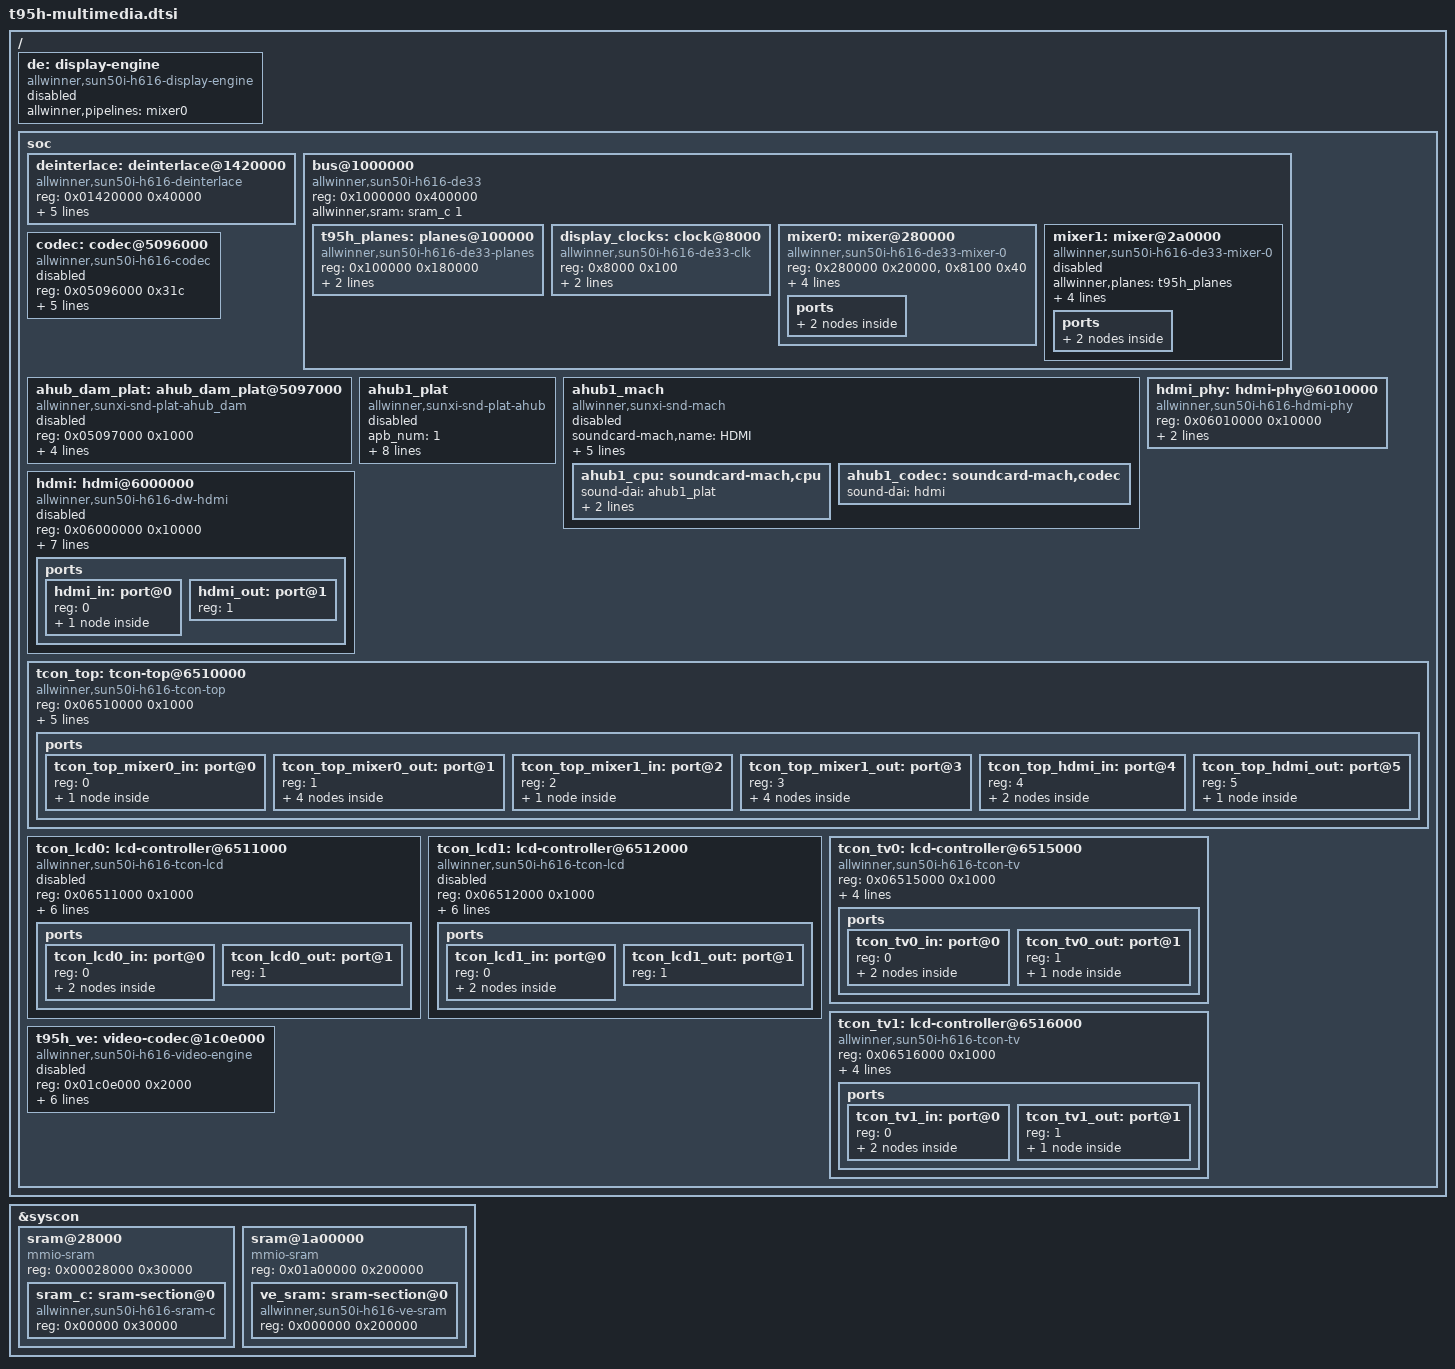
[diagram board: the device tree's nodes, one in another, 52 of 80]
// SPDX-License-Identifier: (GPL-2.0+ OR MIT)
// Staged 6.12 backport of tested T95H multimedia topology.
#include <dt-bindings/clock/sun8i-de2.h>
#include <dt-bindings/clock/sun8i-tcon-top.h>
#include <dt-bindings/reset/sun8i-de2.h>
/ {
	de: display-engine {
		compatible = "allwinner,sun50i-h616-display-engine", "allwinner,sun50i-h6-display-engine";
		allwinner,pipelines = <&mixer0>;
		status = "disabled";
	};
soc {
        deinterlace: deinterlace@1420000 {
            compatible = "allwinner,sun50i-h616-deinterlace";
            reg = <0x01420000 0x40000>;
            clocks = <&ccu CLK_BUS_DEINTERLACE>, <&ccu CLK_DEINTERLACE>;
            clock-names = "bus", "mod";
            resets = <&ccu RST_BUS_DEINTERLACE>;
            interrupts = <GIC_SPI 89 IRQ_TYPE_LEVEL_HIGH>;
            iommus = <&iommu 1>;
            status = "okay";
        };

		bus@1000000 {
			compatible = "allwinner,sun50i-h616-de33",
				     "allwinner,sun50i-a64-de2";
			reg = <0x1000000 0x400000>;
			allwinner,sram = <&sram_c 1>;
			#address-cells = <1>;
			#size-cells = <1>;
			ranges = <0 0x1000000 0x400000>;

			t95h_planes: planes@100000 {
                compatible = "allwinner,sun50i-h616-de33-planes";
                reg = <0x100000 0x180000>;
                allwinner,plane-mapping = <&display_clocks>;
                iommus = <&iommu 0>;
            };
            display_clocks: clock@8000 {
				compatible = "allwinner,sun50i-h616-de33-clk";
				reg = <0x8000 0x100>;
				clocks = <&ccu CLK_BUS_DE>, <&ccu CLK_DE>;
				clock-names = "bus", "mod";
				resets = <&ccu RST_BUS_DE>;
				#clock-cells = <1>;
				#reset-cells = <1>;
			};



			mixer0: mixer@280000 {
				compatible = "allwinner,sun50i-h616-de33-mixer-0";
				reg = <0x280000 0x20000>, <0x8100 0x40>;
				reg-names = "display", "top";
                allwinner,planes = <&t95h_planes>;
				clocks = <&display_clocks CLK_BUS_MIXER0>,
					 <&display_clocks CLK_MIXER0>;
				clock-names = "bus", "mod";
				resets = <&display_clocks RST_MIXER0>;

				ports {
					#address-cells = <1>;
					#size-cells = <0>;

					mixer0_out: port@1 {
						reg = <1>;

						mixer0_out_tcon_top_mixer0: endpoint {
							remote-endpoint =
								<&tcon_top_mixer0_in_mixer0>;
						};
					};
				};
			};

			mixer1: mixer@2a0000 {
                allwinner,planes = <&t95h_planes>;
				status = "disabled";
				compatible = "allwinner,sun50i-h616-de33-mixer-0";
				reg = <0x2a0000 0x20000>,
				      <0x8140 0x40>;
				reg-names = "display", "top";
				clocks = <&display_clocks CLK_BUS_MIXER0>,
					 <&display_clocks CLK_MIXER1>;
				clock-names = "bus", "mod";
				resets = <&display_clocks RST_MIXER1>;

				ports {
					#address-cells = <1>;
					#size-cells = <0>;

					mixer1_out: port@1 {
						reg = <1>;

						mixer1_out_tcon_top_mixer1: endpoint {
							remote-endpoint =
								<&tcon_top_mixer1_in_mixer1>;
						};
					};
				};
			};
		};
		codec: codec@5096000 {
			#sound-dai-cells = <0>;
			compatible = "allwinner,sun50i-h616-codec";
			reg = <0x05096000 0x31c>;
			interrupts = <GIC_SPI 58 IRQ_TYPE_LEVEL_HIGH>;
			clocks = <&ccu CLK_BUS_AUDIO_CODEC>,
				 <&ccu CLK_AUDIO_CODEC_1X>;
			clock-names = "apb", "codec";
			resets = <&ccu RST_BUS_AUDIO_CODEC>;
			dmas = <&dma 6>;
			dma-names = "tx";
			status = "disabled";
		};
		ahub_dam_plat:ahub_dam_plat@5097000 {
			#sound-dai-cells = <0>;
			/* sound card without pcm for hardware mix setting */
			compatible = "allwinner,sunxi-snd-plat-ahub_dam";
			reg        = <0x05097000 0x1000>;
			resets     = <&ccu RST_BUS_AUDIO_HUB>;
			clocks     = <&ccu CLK_AUDIO_CODEC_1X>,
				     <&ccu CLK_AUDIO_CODEC_4X>,
				     <&ccu CLK_AUDIO_HUB>,
				     <&ccu CLK_BUS_AUDIO_HUB>;
                        clock-names =   "clk_pll_audio",
					"clk_pll_audio_4x",
					"clk_audio_hub",
					"clk_bus_audio_hub";
			status = "disabled";
		};
		ahub1_plat:ahub1_plat {
			#sound-dai-cells = <0>;
			compatible      = "allwinner,sunxi-snd-plat-ahub";
			apb_num         = <1>;  /* for dma port 4 */
			dmas            = <&dma 4>, <&dma 4>;
			dma-names       = "tx", "rx";
			playback_cma    = <128>;
			capture_cma     = <128>;
			tx_fifo_size    = <128>;
			rx_fifo_size    = <128>;

			tdm_num         = <1>;
			tx_pin          = <0>;
			rx_pin          = <0>;
			status          = "disabled";
		};
		ahub1_mach:ahub1_mach {
			compatible = "allwinner,sunxi-snd-mach";
			soundcard-mach,name = "HDMI";

			soundcard-mach,format           = "i2s";
			soundcard-mach,frame-master     = <&ahub1_cpu>;
			soundcard-mach,bitclock-master  = <&ahub1_cpu>;
			/* soundcard-mach,frame-inversion; */
			/* soundcard-mach,bitclock-inversion; */
			soundcard-mach,slot-num         = <2>;
			soundcard-mach,slot-width       = <32>;
			status          = "disabled";
			ahub1_cpu: soundcard-mach,cpu {
				sound-dai = <&ahub1_plat>;
				soundcard-mach,pll-fs   = <4>;
				soundcard-mach,mclk-fs  = <0>;
			};

			ahub1_codec: soundcard-mach,codec {
				sound-dai = <&hdmi>;
			};
		};
		hdmi: hdmi@6000000 {
			compatible = "allwinner,sun50i-h616-dw-hdmi",
				     "allwinner,sun50i-h6-dw-hdmi";
			reg = <0x06000000 0x10000>;
			reg-io-width = <1>;
			interrupts = <GIC_SPI 63 IRQ_TYPE_LEVEL_HIGH>;
			clocks = <&ccu CLK_BUS_HDMI>, <&ccu CLK_HDMI_SLOW>,
				 <&ccu CLK_HDMI>, <&ccu CLK_HDMI_CEC>,
				 <&ccu CLK_HDCP>, <&ccu CLK_BUS_HDCP>;
			clock-names = "iahb", "isfr", "tmds", "cec", "hdcp",
				      "hdcp-bus";
			resets = <&ccu RST_BUS_HDMI>, <&ccu RST_BUS_HDCP>;
			reset-names = "ctrl", "hdcp";
			phys = <&hdmi_phy>;
			phy-names = "phy";
			status = "disabled";

			ports {
				#address-cells = <1>;
				#size-cells = <0>;

				hdmi_in: port@0 {
					reg = <0>;

					hdmi_in_tcon_top: endpoint {
						remote-endpoint = <&tcon_top_hdmi_out_hdmi>;
					};
				};

				hdmi_out: port@1 {
					reg = <1>;
				};
			};
		};
		hdmi_phy: hdmi-phy@6010000 {
			compatible = "allwinner,sun50i-h616-hdmi-phy";
			reg = <0x06010000 0x10000>;
			clocks = <&ccu CLK_BUS_HDMI>, <&ccu CLK_HDMI_SLOW>;
			clock-names = "bus", "mod";
			resets = <&ccu RST_BUS_HDMI_SUB>;
			reset-names = "phy";
			#phy-cells = <0>;
		};
		tcon_top: tcon-top@6510000 {
			compatible = "allwinner,sun50i-h616-tcon-top";
			reg = <0x06510000 0x1000>;
			clocks = <&ccu CLK_BUS_TCON_TOP>,
				 <&ccu CLK_TCON_TV0>,
				 <&ccu CLK_TVE0>,
				 <&ccu CLK_TCON_TV1>;
			clock-names = "bus",
				      "tcon-tv0",
				      "tve0",
				      "tcon-tv1";
			clock-output-names = "tcon-top-tv0",
					     "tcon-top-tv1";
			resets = <&ccu RST_BUS_TCON_TOP>;
			#clock-cells = <1>;

			ports {
				#address-cells = <1>;
				#size-cells = <0>;

				tcon_top_mixer0_in: port@0 {
					#address-cells = <1>;
					#size-cells = <0>;
					reg = <0>;

					tcon_top_mixer0_in_mixer0: endpoint@0 {
						reg = <0>;
						remote-endpoint = <&mixer0_out_tcon_top_mixer0>;
					};
				};

				tcon_top_mixer0_out: port@1 {
					#address-cells = <1>;
					#size-cells = <0>;
					reg = <1>;

					tcon_top_mixer0_out_tcon_lcd0: endpoint@0 {
						reg = <0>;
						remote-endpoint = <&tcon_lcd0_in_tcon_top_mixer0>;
					};

					tcon_top_mixer0_out_tcon_lcd1: endpoint@1 {
						reg = <1>;
						remote-endpoint = <&tcon_lcd1_in_tcon_top_mixer0>;
					};

					tcon_top_mixer0_out_tcon_tv0: endpoint@2 {
						reg = <2>;
						remote-endpoint = <&tcon_tv0_in_tcon_top_mixer0>;
					};

					tcon_top_mixer0_out_tcon_tv1: endpoint@3 {
						reg = <3>;
						remote-endpoint = <&tcon_tv1_in_tcon_top_mixer0>;
					};
				};

				tcon_top_mixer1_in: port@2 {
					#address-cells = <1>;
					#size-cells = <0>;
					reg = <2>;

					tcon_top_mixer1_in_mixer1: endpoint@1 {
						reg = <1>;
						remote-endpoint = <&mixer1_out_tcon_top_mixer1>;
					};
				};

				tcon_top_mixer1_out: port@3 {
					#address-cells = <1>;
					#size-cells = <0>;
					reg = <3>;

					tcon_top_mixer1_out_tcon_lcd0: endpoint@0 {
						reg = <0>;
						remote-endpoint = <&tcon_lcd0_in_tcon_top_mixer1>;
					};

					tcon_top_mixer1_out_tcon_lcd1: endpoint@1 {
						reg = <1>;
						remote-endpoint = <&tcon_lcd1_in_tcon_top_mixer1>;
					};

					tcon_top_mixer1_out_tcon_tv0: endpoint@2 {
						reg = <2>;
						remote-endpoint = <&tcon_tv0_in_tcon_top_mixer1>;
					};

					tcon_top_mixer1_out_tcon_tv1: endpoint@3 {
						reg = <3>;
						remote-endpoint = <&tcon_tv1_in_tcon_top_mixer1>;
					};
				};

				tcon_top_hdmi_in: port@4 {
					#address-cells = <1>;
					#size-cells = <0>;
					reg = <4>;

					tcon_top_hdmi_in_tcon_tv0: endpoint@0 {
						reg = <0>;
						remote-endpoint = <&tcon_tv0_out_tcon_top>;
					};

					tcon_top_hdmi_in_tcon_tv1: endpoint@1 {
						reg = <1>;
						remote-endpoint = <&tcon_tv1_out_tcon_top>;
					};
				};

				tcon_top_hdmi_out: port@5 {
					reg = <5>;

					tcon_top_hdmi_out_hdmi: endpoint {
						remote-endpoint = <&hdmi_in_tcon_top>;
					};
				};
			};
		};
		tcon_lcd0: lcd-controller@6511000 {
			compatible = "allwinner,sun50i-h616-tcon-lcd",
				     "allwinner,sun8i-r40-tcon-lcd";
			reg = <0x06511000 0x1000>;
			interrupts = <GIC_SPI 64 IRQ_TYPE_LEVEL_HIGH>;
			clocks = <&ccu CLK_BUS_TCON_LCD0>, <&ccu CLK_TCON_LCD0>;
			clock-names = "ahb", "tcon-ch0";
			clock-output-names = "tcon-data-clock";
			#clock-cells = <0>;
			resets = <&ccu RST_BUS_TCON_LCD0>, <&ccu RST_BUS_LVDS>;
			reset-names = "lcd", "lvds";
			status = "disabled";

			ports {
				#address-cells = <1>;
				#size-cells = <0>;

				tcon_lcd0_in: port@0 {
					#address-cells = <1>;
					#size-cells = <0>;
					reg = <0>;

					tcon_lcd0_in_tcon_top_mixer0: endpoint@0 {
						reg = <0>;
						remote-endpoint = <&tcon_top_mixer0_out_tcon_lcd0>;
					};

					tcon_lcd0_in_tcon_top_mixer1: endpoint@1 {
						reg = <1>;
						remote-endpoint = <&tcon_top_mixer1_out_tcon_lcd0>;
					};
				};

				tcon_lcd0_out: port@1 {
					reg = <1>;
				};
			};
		};
		tcon_lcd1: lcd-controller@6512000 {
			compatible = "allwinner,sun50i-h616-tcon-lcd",
				     "allwinner,sun8i-r40-tcon-lcd";
			reg = <0x06512000 0x1000>;
			interrupts = <GIC_SPI 65 IRQ_TYPE_LEVEL_HIGH>;
			clocks = <&ccu CLK_BUS_TCON_LCD1>, <&ccu CLK_TCON_LCD1>;
			clock-names = "ahb", "tcon-ch0";
			clock-output-names = "tcon-data-clock";
			#clock-cells = <0>;
			resets = <&ccu RST_BUS_TCON_LCD1>, <&ccu RST_BUS_LVDS>;
			reset-names = "lcd", "lvds";
			status = "disabled";

			ports {
				#address-cells = <1>;
				#size-cells = <0>;

				tcon_lcd1_in: port@0 {
					#address-cells = <1>;
					#size-cells = <0>;
					reg = <0>;

					tcon_lcd1_in_tcon_top_mixer0: endpoint@0 {
						reg = <0>;
						remote-endpoint = <&tcon_top_mixer0_out_tcon_lcd1>;
					};

					tcon_lcd1_in_tcon_top_mixer1: endpoint@1 {
						reg = <1>;
						remote-endpoint = <&tcon_top_mixer1_out_tcon_lcd1>;
					};
				};

				tcon_lcd1_out: port@1 {
					reg = <1>;
				};
			};
		};
		tcon_tv0: lcd-controller@6515000 {
			compatible = "allwinner,sun50i-h616-tcon-tv";
			reg = <0x06515000 0x1000>;
			interrupts = <GIC_SPI 66 IRQ_TYPE_LEVEL_HIGH>;
			clocks = <&ccu CLK_BUS_TCON_TV0>,
				 <&tcon_top CLK_TCON_TOP_TV0>;
			clock-names = "ahb",
				      "tcon-ch1";
			resets = <&ccu RST_BUS_TCON_TV0>;
			reset-names = "lcd";

			ports {
				#address-cells = <1>;
				#size-cells = <0>;

				tcon_tv0_in: port@0 {
					#address-cells = <1>;
					#size-cells = <0>;
					reg = <0>;

					tcon_tv0_in_tcon_top_mixer0: endpoint@0 {
						reg = <0>;
						remote-endpoint = <&tcon_top_mixer0_out_tcon_tv0>;
					};

					tcon_tv0_in_tcon_top_mixer1: endpoint@1 {
						reg = <1>;
						remote-endpoint = <&tcon_top_mixer1_out_tcon_tv0>;
					};
				};

				tcon_tv0_out: port@1 {
					#address-cells = <1>;
					#size-cells = <0>;
					reg = <1>;

					tcon_tv0_out_tcon_top: endpoint@1 {
						reg = <1>;
						remote-endpoint = <&tcon_top_hdmi_in_tcon_tv0>;
					};
				};
			};
		};
		tcon_tv1: lcd-controller@6516000 {
			compatible = "allwinner,sun50i-h616-tcon-tv";
			reg = <0x06516000 0x1000>;
			interrupts = <GIC_SPI 67 IRQ_TYPE_LEVEL_HIGH>;
			clocks = <&ccu CLK_BUS_TCON_TV1>,
				 <&tcon_top CLK_TCON_TOP_TV1>;
			clock-names = "ahb",
				      "tcon-ch1";
			resets = <&ccu RST_BUS_TCON_TV1>;
			reset-names = "lcd";

			ports {
				#address-cells = <1>;
				#size-cells = <0>;

				tcon_tv1_in: port@0 {
					#address-cells = <1>;
					#size-cells = <0>;
					reg = <0>;

					tcon_tv1_in_tcon_top_mixer0: endpoint@0 {
						reg = <0>;
						remote-endpoint = <&tcon_top_mixer0_out_tcon_tv1>;
					};

					tcon_tv1_in_tcon_top_mixer1: endpoint@1 {
						reg = <1>;
						remote-endpoint = <&tcon_top_mixer1_out_tcon_tv1>;
					};
				};

				tcon_tv1_out: port@1 {
					#address-cells = <1>;
					#size-cells = <0>;
					reg = <1>;

					tcon_tv1_out_tcon_top: endpoint@1 {
						reg = <1>;
						remote-endpoint = <&tcon_top_hdmi_in_tcon_tv1>;
					};
				};
			};
		};
};
};
&syscon {
/delete-node/ sram@28000;
			sram@28000 {
				compatible = "mmio-sram";
				reg = <0x00028000 0x30000>;
				#address-cells = <1>;
				#size-cells = <1>;
				ranges = <0 0x00028000 0x30000>;

				/*
				 * 0x0 ~ 0x20000 is partial alias of VE SRAM below.
				 * 0x20000 ~ 0x2ffff is (partial?) alias of DE SRAM.
				 * However the whole region is toggled together.
				 */
				sram_c: sram-section@0 {
					compatible = "allwinner,sun50i-h616-sram-c",
						     "allwinner,sun50i-a64-sram-c";
					reg = <0x00000 0x30000>;
				};
			};
			sram@1a00000 {
				compatible = "mmio-sram";
				reg = <0x01a00000 0x200000>;
				#address-cells = <1>;
				#size-cells = <1>;
				ranges = <0 0x01a00000 0x200000>;

				ve_sram: sram-section@0 {
					compatible = "allwinner,sun50i-h616-ve-sram";
					reg = <0x000000 0x200000>;
				};
			};
};

/* Keep the same decoder SRAM and IOMMU wiring as the tested reference DT. */
/ { soc { t95h_ve: video-codec@1c0e000 {
 compatible = "allwinner,sun50i-h616-video-engine";
 reg = <0x01c0e000 0x2000>;
 interrupts = <GIC_SPI 93 IRQ_TYPE_LEVEL_HIGH>;
 clocks = <&ccu CLK_BUS_VE>, <&ccu CLK_VE>, <&ccu CLK_MBUS_VE>;
 clock-names = "ahb", "mod", "ram";
 resets = <&ccu RST_BUS_VE>;
 iommus = <&iommu 3>, <&iommu 2>;
 allwinner,sram = <&ve_sram 1>, <&sram_c 1>;
 status = "disabled";
}; }; };
&hdmi { #sound-dai-cells = <0>; };
